AUTOSAR XML (schema 4-1-0)
standard types defined: uint16, uint8
package /Cluster
  can cluster CAN
    can physical channel CAN
      frame FRAME_ESP_Status: id 0x120, from GW, to BCM, frame-length=8, can-addressing-mode=STANDARD  # Chassis state the BCM needs: put on the bus by the gateway from VSS (the browser plays the ESP).
        pdu PDU_ESP_Status: length=8, transmission-mode-true-timing=cyclic-timing=time-period=0.05
          signal ESP_VehicleSpeed: start 0, 16 bit, little-endian, base-type=uint16, compu {phys=raw*0.01}, unit=km/h, to BCM
          signal ESP_BrakePedalPos: start 16, 8 bit, little-endian, base-type=uint8, compu {phys=raw}, unit=%, to BCM
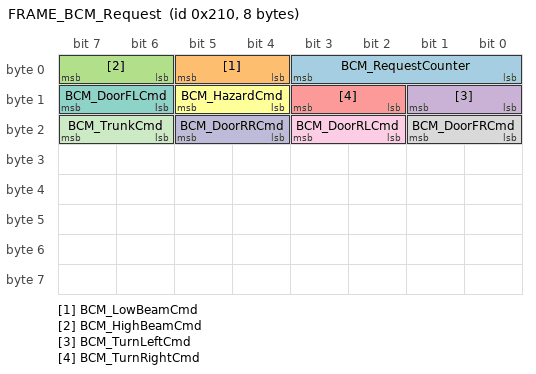
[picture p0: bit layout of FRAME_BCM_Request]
      frame FRAME_BCM_Request: id 0x210, from GW, to BCM, frame-length=8, can-addressing-mode=STANDARD  # Event commands to the BCM. A new BCM_RequestCounter value marks a new command set; NO_REQUEST leaves a function unchanged.
        pdu PDU_BCM_Request: length=8, transmission-mode-true-timing=cyclic-timing=time-period=0.1
          signal BCM_RequestCounter: start 0, 4 bit, little-endian, base-type=uint8, compu {phys=raw}, unit=BCM_RequestCounter, to BCM  # Incremented by the sender for every new command set; repeats with the same value are ignored.
          signal BCM_LowBeamCmd: start 4, 2 bit, little-endian, base-type=uint8, compu {0=NO_REQUEST, 1=OFF, 2=ON, phys=raw}, unit=BCM_LowBeamCmd, to BCM
          signal BCM_HighBeamCmd: start 6, 2 bit, little-endian, base-type=uint8, compu {0=NO_REQUEST, 1=OFF, 2=ON, phys=raw}, unit=BCM_HighBeamCmd, to BCM
          signal BCM_TurnLeftCmd: start 8, 2 bit, little-endian, base-type=uint8, compu {0=NO_REQUEST, 1=OFF, 2=ON, phys=raw}, unit=BCM_TurnLeftCmd, to BCM
          signal BCM_TurnRightCmd: start 10, 2 bit, little-endian, base-type=uint8, compu {0=NO_REQUEST, 1=OFF, 2=ON, phys=raw}, unit=BCM_TurnRightCmd, to BCM
          signal BCM_HazardCmd: start 12, 2 bit, little-endian, base-type=uint8, compu {0=NO_REQUEST, 1=OFF, 2=ON, phys=raw}, unit=BCM_HazardCmd, to BCM
          signal BCM_DoorFLCmd: start 14, 2 bit, little-endian, base-type=uint8, compu {0=NO_REQUEST, 1=CLOSE, 2=OPEN, phys=raw}, unit=BCM_DoorFLCmd, to BCM
          signal BCM_DoorFRCmd: start 16, 2 bit, little-endian, base-type=uint8, compu {0=NO_REQUEST, 1=CLOSE, 2=OPEN, phys=raw}, unit=BCM_DoorFRCmd, to BCM
          signal BCM_DoorRLCmd: start 18, 2 bit, little-endian, base-type=uint8, compu {0=NO_REQUEST, 1=CLOSE, 2=OPEN, phys=raw}, unit=BCM_DoorRLCmd, to BCM
          signal BCM_DoorRRCmd: start 20, 2 bit, little-endian, base-type=uint8, compu {0=NO_REQUEST, 1=CLOSE, 2=OPEN, phys=raw}, unit=BCM_DoorRRCmd, to BCM
          signal BCM_TrunkCmd: start 22, 2 bit, little-endian, base-type=uint8, compu {0=NO_REQUEST, 1=CLOSE, 2=OPEN, phys=raw}, unit=BCM_TrunkCmd, to BCM
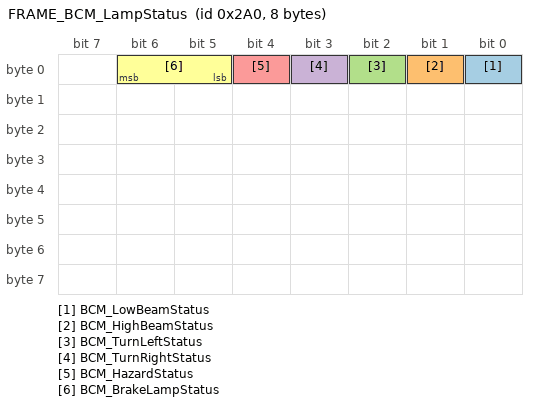
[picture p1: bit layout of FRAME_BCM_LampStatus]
      frame FRAME_BCM_LampStatus: id 0x2A0, from BCM, to GW, frame-length=8, can-addressing-mode=STANDARD  # Lamp outputs as driven by the BCM.
        pdu PDU_BCM_LampStatus: length=8, transmission-mode-true-timing=cyclic-timing=time-period=0.1
          signal BCM_LowBeamStatus: start 0, 1 bit, little-endian, base-type=uint8, compu {phys=raw}, unit=BCM_LowBeamStatus, to GW
          signal BCM_HighBeamStatus: start 1, 1 bit, little-endian, base-type=uint8, compu {phys=raw}, unit=BCM_HighBeamStatus, to GW
          signal BCM_TurnLeftStatus: start 2, 1 bit, little-endian, base-type=uint8, compu {phys=raw}, unit=BCM_TurnLeftStatus, to GW
          signal BCM_TurnRightStatus: start 3, 1 bit, little-endian, base-type=uint8, compu {phys=raw}, unit=BCM_TurnRightStatus, to GW
          signal BCM_HazardStatus: start 4, 1 bit, little-endian, base-type=uint8, compu {phys=raw}, unit=BCM_HazardStatus, to GW
          signal BCM_BrakeLampStatus: start 5, 2 bit, little-endian, base-type=uint8, compu {0=LIGHT_OFF, 1=LIGHT_ON, 2=LIGHT_FAULT, 3=LIGHT_SNA, phys=raw}, unit=BCM_BrakeLampStatus, to GW
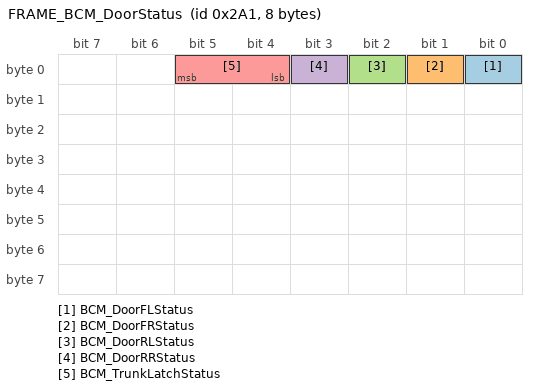
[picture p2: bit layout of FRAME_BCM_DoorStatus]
      frame FRAME_BCM_DoorStatus: id 0x2A1, from BCM, to GW, frame-length=8, can-addressing-mode=STANDARD  # Door and trunk latch state as reported by the BCM.
        pdu PDU_BCM_DoorStatus: length=8, transmission-mode-true-timing=cyclic-timing=time-period=0.1
          signal BCM_DoorFLStatus: start 0, 1 bit, little-endian, base-type=uint8, compu {phys=raw}, unit=BCM_DoorFLStatus, to GW
          signal BCM_DoorFRStatus: start 1, 1 bit, little-endian, base-type=uint8, compu {phys=raw}, unit=BCM_DoorFRStatus, to GW
          signal BCM_DoorRLStatus: start 2, 1 bit, little-endian, base-type=uint8, compu {phys=raw}, unit=BCM_DoorRLStatus, to GW
          signal BCM_DoorRRStatus: start 3, 1 bit, little-endian, base-type=uint8, compu {phys=raw}, unit=BCM_DoorRRStatus, to GW
          signal BCM_TrunkLatchStatus: start 4, 2 bit, little-endian, base-type=uint8, compu {0=LATCH_CLOSED, 1=LATCH_OPENED, 2=LATCH_AJAR, 3=LATCH_FAULT, phys=raw}, unit=BCM_TrunkLatchStatus, to GW
package /DataType/Unit
  24 x unit:
    ESP_VehicleSpeed: display-name=km/h
    ESP_BrakePedalPos: display-name=%
    BCM_RequestCounter
    BCM_LowBeamCmd
    BCM_HighBeamCmd
    BCM_TurnLeftCmd
    BCM_TurnRightCmd
    BCM_HazardCmd
    BCM_DoorFLCmd
    BCM_DoorFRCmd
    BCM_DoorRLCmd
    BCM_DoorRRCmd
    BCM_TrunkCmd
    BCM_LowBeamStatus
    BCM_HighBeamStatus
    BCM_TurnLeftStatus
    BCM_TurnRightStatus
    BCM_HazardStatus
    BCM_BrakeLampStatus
    BCM_DoorFLStatus
    BCM_DoorFRStatus
    BCM_DoorRLStatus
    BCM_DoorRRStatus
    BCM_TrunkLatchStatus
package /ECU
  ecu instance GW: associated-com-i-pdu-group=[GW_Rx, GW_Tx]
    can communication connector CN_GW
  ecu instance BCM: associated-com-i-pdu-group=[BCM_Rx, BCM_Tx]
    can communication connector CN_BCM
package /IPDUGroup
  4 x i signal i pdu group:
    GW_Tx: communication-direction=OUT, i-signal-i-pdus=[PDU_ESP_Status, PDU_BCM_Request]
    BCM_Tx: communication-direction=OUT, i-signal-i-pdus=[PDU_BCM_LampStatus, PDU_BCM_DoorStatus]
    GW_Rx: communication-direction=IN, i-signal-i-pdus=[PDU_BCM_LampStatus, PDU_BCM_DoorStatus]
    BCM_Rx: communication-direction=IN, i-signal-i-pdus=[PDU_ESP_Status, PDU_BCM_Request]
